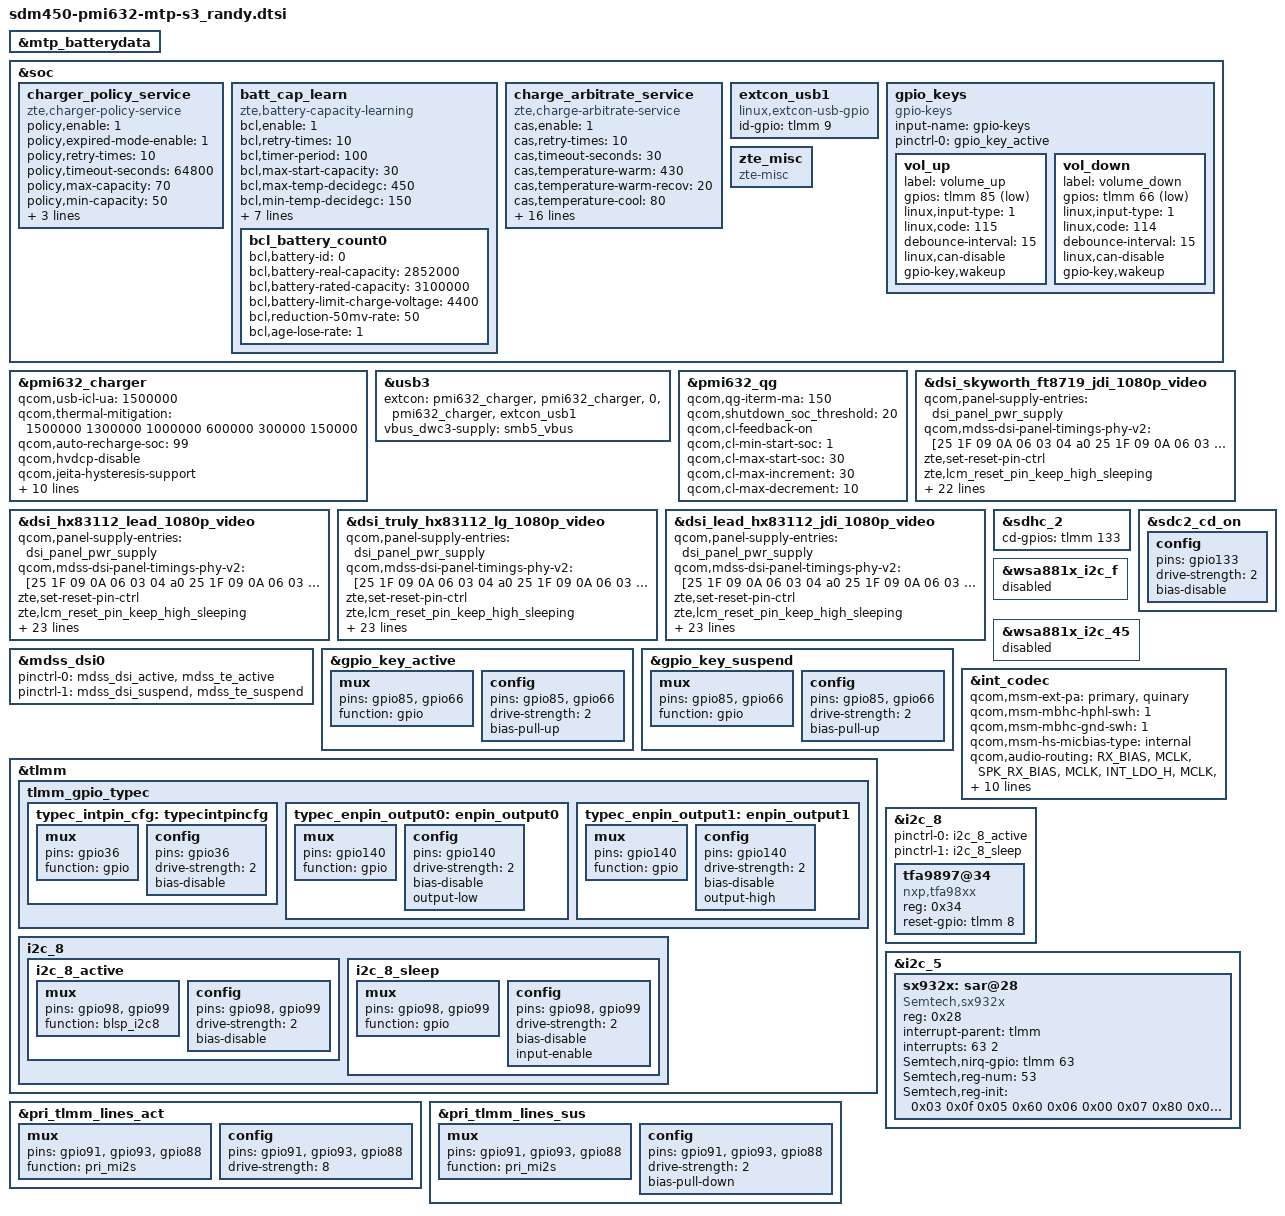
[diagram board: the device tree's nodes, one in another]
#include "dsi-panel-zte-lead-hx83112-lg-6p0-1080p-video-success.dtsi"
#include "dsi-panel-zte-truly-hx83112-lg-6p0-1080p-video.dtsi"
#include "dsi-panel-zte-lead-hx83112-jdi-6p0-1080p-video.dtsi"
#include "dsi-panel-zte-skyworth-ft8719-jdi-6p0-1080p-video.dtsi"

#include "zte-usb-type-c.dtsi"
#include "touchscreen-randy.dtsi"
#include "fingerprint_randy.dtsi"
#include "zte-sdm450-camera-sensor-mtp-randy.dtsi"

&mtp_batterydata {
	#include "zte_p450a01_3100mAh.dtsi"
};

&soc {
	charger_policy_service {
		compatible = "zte,charger-policy-service";
		policy,enable = <1>;
		policy,expired-mode-enable = <1>;
		policy,retry-times = <10>;
		policy,timeout-seconds = <64800>;/* 18 hours */
		policy,max-capacity = <70>;
		policy,min-capacity = <50>;
		policy,bms-phy-name = "bms";
		policy,battery-phy-name = "battery";
		policy,cas-phy-name = "cas";
	};

	batt_cap_learn {
		compatible = "zte,battery-capacity-learning";
		bcl,enable = <1>;
		bcl,retry-times = <10>;
		bcl,timer-period = <100>;/*ms*/
		bcl,max-start-capacity = <30>;
		bcl,max-temp-decidegc = <450>;
		bcl,min-temp-decidegc = <150>;
		bcl,max-limit-deciperc = <100>;
		bcl,min-limit-deciperc = <50>;
		bcl,max-increment-deciperc = <5>;
		bcl,max-decrement-deciperc = <5>;
		bcl,bms-phy-name = "bms";
		bcl,battery-phy-name = "battery";
		/*bit7: 0: use zte algorithm calc age; 1: use platform algorithm calc age*/
		/*bit4: enable zte algorithm*/
		/*bit3: enable platform algorithm*/
		/*bit0: platform algorithm mode 0: integral mode; 1: delta mode*/
		bcl,algorithm-select = <0x88>;

		bcl_battery_count0 {
			bcl,battery-id = <0>;
			/*"real capacity" = "rated capacity" - "voltage diff" - "topoff diff"*/
			/*TMB TEST REAL CAPACITY 92%*/
			bcl,battery-real-capacity = <2852000>;
			bcl,battery-rated-capacity = <3100000>;
			bcl,battery-limit-charge-voltage = <4400>;
			bcl,reduction-50mv-rate = <50>;/*rate * 10*/
			bcl,age-lose-rate = <1>;/*rate * 10*/
		};
	};

	charge_arbitrate_service {
		compatible = "zte,charge-arbitrate-service";
		cas,enable = <1>;
		cas,retry-times = <10>;
		cas,timeout-seconds = <30>;/*s*/
		cas,temperature-warm = <430>;
		cas,temperature-warm-recov = <20>;
		cas,temperature-cool = <80>;
		cas,temperature-cool-recov = <20>;
		cas,normal-topoff = <5>;
		cas,abnormal-topoff = <9>;
		cas,force-full-aging = <1>;
		cas,subsidiary-phy-name = "bms";
		cas,battery-phy-name = "battery";
		cas,bcl-phy-name = "bcl";
		cas,fcv-phy = "battery";
		cas,fcc-phy = "battery";
		cas,icl-phy = "battery";
		cas,topoff-phy = "battery";
		cas,recharge-soc-phy = "battery";
		cas,recharge-voltage-phy = "battery";
		cas,voltage-cc-cv-phy = "bms";
		/* age, fcv, fcc, rech_soc_1st, rech_soc_2st rech_vol_1st, rech_vol_2st **/
		cas,age-data = <100 4400000 2000000 99 95 0 0
				95 4380000 1800000 98 94 0 0
				90 4360000 1600000 97 93 0 0
				85 4340000 1400000 96 92 0 0
				80 4320000 1200000 95 91 0 0
				75 4300000 1000000 94 90 0 0>;
	};
};

&pmi632_charger {
	qcom,usb-icl-ua = <1500000>;
	qcom,thermal-mitigation
		= <1500000 1300000 1000000 600000
			300000 150000>;
	qcom,auto-recharge-soc = <99>;
	qcom,hvdcp-disable;
	qcom,jeita-hysteresis-support;

	/* COOL = 10 DegC, WARM = 45 DegC */
	qcom,jeita-soft-thresholds = <0x3772 0x12d2>;
	/* COLD = 0 DegC, HOT = 60 DegC */
	qcom,jeita-hard-thresholds = <0x45f5 0xb71>;

	/* COOL = 2 DegC, WARM = 60 DegC */
	qcom,jeita-cold-hysteresis-thresholds = <0x430E 0xB71>;
	/* COLD = 12 DegC, HOT = 45 DegC */
	qcom,jeita-cool-hysteresis-thresholds = <0x349E 0x12D2>;
	/* COOL = 10 DegC, WARM = 43 DegC */
	qcom,jeita-warm-hysteresis-thresholds = <0x3772 0x141E>;
	/* COLD = 0 DegC, HOT = 58 DegC */
	qcom,jeita-hot-hysteresis-thresholds = <0x45F5 0xC38>;
};

/*typec*/
&usb3 {
	extcon = <&pmi632_charger>, <&pmi632_charger>, <0>,
		<&pmi632_charger>, <&extcon_usb1>;
	vbus_dwc3-supply = <&smb5_vbus>;
};

&soc {
	extcon_usb1: extcon_usb1 {
		compatible = "linux,extcon-usb-gpio";
		id-gpio = <&tlmm 9 0>;
/*		pinctrl-names = "default";  */
/*		pinctrl-0 = <&usb_id_default>;*/
	};
};

/*typec*/

&pmi632_qg {
	qcom,qg-iterm-ma = <150>;
	qcom,shutdown_soc_threshold = <20>;
	qcom,cl-feedback-on;
	qcom,cl-min-start-soc = <1>;
	qcom,cl-max-start-soc = <30>;
	qcom,cl-max-increment = <30>;
	qcom,cl-max-decrement = <10>;
};

&dsi_skyworth_ft8719_jdi_1080p_video{
	qcom,panel-supply-entries = <&dsi_panel_pwr_supply>;
	qcom,mdss-dsi-panel-timings-phy-v2 = [25 1F 09 0A 06 03 04 a0
		25 1F 09 0A 06 03 04 a0
		25 1F 09 0A 06 03 04 a0
		25 1F 09 0A 06 03 04 a0
		25 1D 08 0A 06 03 04 a0];
	zte,set-reset-pin-ctrl;
	zte,lcm_reset_pin_keep_high_sleeping;
	zte,mdss-dsi-cabc-default-value = <0x02>;
	zte,mdss-dsi-cabc-off-command = [39 01 00 00 00 00 02 55 00
	];
	zte,mdss-dsi-cabc-low-command = [39 01 00 00 00 00 02 55 11
	];
	zte,mdss-dsi-cabc-medium-command = [39 01 00 00 00 00 02 55 12
	];
	zte,mdss-dsi-cabc-high-command = [39 01 00 00 00 00 02 55 13
	];
	zte,mdss-dsi-cabc-command-state = "dsi_lp_mode";
//	qcom,esd-check-enabled;
	qcom,mdss-dsi-panel-status-check-mode = "reg_read";
	qcom,mdss-dsi-panel-status-command = [06 01 00 01 00 00 01 0a];
	qcom,mdss-dsi-panel-status-command-state = "dsi_lp_mode";
	qcom,mdss-dsi-panel-status-value = <0x9c 0x9c 0x9c 0x9c>;
	qcom,mdss-dsi-panel-on-check-value = <0x9c 0x9c 0x9c 0x9c>;
	qcom,mdss-dsi-panel-status-read-length = <4>;
	qcom,mdss-dsi-panel-max-error-count = <3>;
};



&dsi_hx83112_lead_1080p_video{
	qcom,panel-supply-entries = <&dsi_panel_pwr_supply>;
	qcom,mdss-dsi-panel-timings-phy-v2 = [25 1F 09 0A 06 03 04 a0
		25 1F 09 0A 06 03 04 a0
		25 1F 09 0A 06 03 04 a0
		25 1F 09 0A 06 03 04 a0
		25 1D 08 0A 06 03 04 a0];
	zte,set-reset-pin-ctrl;
	zte,lcm_reset_pin_keep_high_sleeping;
	zte,mdss-dsi-cabc-default-value = <0x02>;
	zte,mdss-dsi-cabc-off-command = [39 01 00 00 00 00 02 55 00
	];
	zte,mdss-dsi-cabc-low-command = [39 01 00 00 00 00 02 55 11
	];
	zte,mdss-dsi-cabc-medium-command = [39 01 00 00 00 00 02 55 12
	];
	zte,mdss-dsi-cabc-high-command = [39 01 00 00 00 00 02 55 13
	];
	zte,mdss-dsi-cabc-command-state = "dsi_lp_mode";
	qcom,esd-check-enabled;
	qcom,mdss-dsi-panel-status-check-mode = "reg_read";
	qcom,mdss-dsi-panel-status-command = [06 01 00 01 00 00 01 0a];
	qcom,mdss-dsi-panel-status-command-state = "dsi_lp_mode";
	qcom,mdss-dsi-panel-status-value = <0x9d 0x9d 0x9d 0x9d>;
	qcom,mdss-dsi-panel-on-check-value = <0x9d 0x9d 0x9d 0x9d>;
	qcom,mdss-dsi-panel-status-read-length = <4>;
	qcom,mdss-dsi-panel-max-error-count = <3>;
};

&dsi_truly_hx83112_lg_1080p_video{
	qcom,panel-supply-entries = <&dsi_panel_pwr_supply>;
	qcom,mdss-dsi-panel-timings-phy-v2 = [25 1F 09 0A 06 03 04 a0
		25 1F 09 0A 06 03 04 a0
		25 1F 09 0A 06 03 04 a0
		25 1F 09 0A 06 03 04 a0
		25 1D 08 0A 06 03 04 a0];
	zte,set-reset-pin-ctrl;
	zte,lcm_reset_pin_keep_high_sleeping;
	zte,mdss-dsi-cabc-default-value = <0x02>;
	zte,mdss-dsi-cabc-off-command = [39 01 00 00 00 00 02 55 00
	];
	zte,mdss-dsi-cabc-low-command = [39 01 00 00 00 00 02 55 11
	];
	zte,mdss-dsi-cabc-medium-command = [39 01 00 00 00 00 02 55 12
	];
	zte,mdss-dsi-cabc-high-command = [39 01 00 00 00 00 02 55 13
	];
	zte,mdss-dsi-cabc-command-state = "dsi_lp_mode";
	qcom,esd-check-enabled;
	qcom,mdss-dsi-panel-status-check-mode = "reg_read";
	qcom,mdss-dsi-panel-status-command = [06 01 00 01 00 00 01 0a];
	qcom,mdss-dsi-panel-status-command-state = "dsi_lp_mode";
	qcom,mdss-dsi-panel-status-value = <0x9d 0x9d 0x9d 0x9d>;
	qcom,mdss-dsi-panel-on-check-value = <0x9d 0x9d 0x9d 0x9d>;
	qcom,mdss-dsi-panel-status-read-length = <4>;
	qcom,mdss-dsi-panel-max-error-count = <3>;
};

&dsi_lead_hx83112_jdi_1080p_video{
	qcom,panel-supply-entries = <&dsi_panel_pwr_supply>;
	qcom,mdss-dsi-panel-timings-phy-v2 = [25 1F 09 0A 06 03 04 a0
		25 1F 09 0A 06 03 04 a0
		25 1F 09 0A 06 03 04 a0
		25 1F 09 0A 06 03 04 a0
		25 1D 08 0A 06 03 04 a0];
	zte,set-reset-pin-ctrl;
	zte,lcm_reset_pin_keep_high_sleeping;
	zte,mdss-dsi-cabc-default-value = <0x02>;
	zte,mdss-dsi-cabc-off-command = [39 01 00 00 00 00 02 55 00
	];
	zte,mdss-dsi-cabc-low-command = [39 01 00 00 00 00 02 55 11
	];
	zte,mdss-dsi-cabc-medium-command = [39 01 00 00 00 00 02 55 12
	];
	zte,mdss-dsi-cabc-high-command = [39 01 00 00 00 00 02 55 13
	];
	zte,mdss-dsi-cabc-command-state = "dsi_lp_mode";
	qcom,esd-check-enabled;
	qcom,mdss-dsi-panel-status-check-mode = "reg_read";
	qcom,mdss-dsi-panel-status-command = [06 01 00 01 00 00 01 0a];
	qcom,mdss-dsi-panel-status-command-state = "dsi_lp_mode";
	qcom,mdss-dsi-panel-status-value = <0x9d 0x9d 0x9d 0x9d>;
	qcom,mdss-dsi-panel-on-check-value = <0x9d 0x9d 0x9d 0x9d>;
	qcom,mdss-dsi-panel-status-read-length = <4>;
	qcom,mdss-dsi-panel-max-error-count = <3>;
};


&mdss_dsi0 {
	pinctrl-0 = <&mdss_dsi_active &mdss_te_active>;
	pinctrl-1 = <&mdss_dsi_suspend &mdss_te_suspend>;
 };

&soc {
	gpio_keys {
		compatible = "gpio-keys";
		input-name = "gpio-keys";
		pinctrl-names = "default";
		pinctrl-0 = <&gpio_key_active>;

		/delete-node/ camera_focus;
		/delete-node/ camera_snapshot;
		vol_up {
			label = "volume_up";
			gpios = <&tlmm 85 0x1>;
			linux,input-type = <1>;
			linux,code = <115>;
			debounce-interval = <15>;
			linux,can-disable;
			gpio-key,wakeup;
		};
		vol_down {
			label = "volume_down";
			gpios = <&tlmm 66 0x1>;
			linux,input-type = <1>;
			linux,code = <114>;
			debounce-interval = <15>;
			linux,can-disable;
			gpio-key,wakeup;
		};
	};

	zte_misc {
		compatible = "zte-misc";
	};
};
&gpio_key_active {
	mux {
		pins = "gpio85", "gpio66";
		function = "gpio";
	};
	config {
		pins = "gpio85", "gpio66";
		drive-strength = <2>;
		bias-pull-up;
	};
};
&gpio_key_suspend {
	mux {
		pins = "gpio85", "gpio66";
		function = "gpio";
	};
	config {
		pins = "gpio85", "gpio66";
		drive-strength = <2>;
		bias-pull-up;
	};
};

&tlmm {
/* zte typec */
	tlmm_gpio_typec {
		typec_intpin_cfg: typecintpincfg {
				mux {
					pins = "gpio36";
					function = "gpio";
				};
				config {
					pins = "gpio36";
					drive-strength = <2>;
					bias-disable;
				};
		};
		typec_enpin_output0: enpin_output0 {
				mux {
					pins = "gpio140";
					function = "gpio";
				};
				config {
					pins = "gpio140";
					drive-strength = <2>;
					bias-disable;
					output-low;
				};
		};
		typec_enpin_output1: enpin_output1 {
				mux {
					pins = "gpio140";
					function = "gpio";
				};
				config {
					pins = "gpio140";
					drive-strength = <2>;
					bias-disable;
					output-high;
				};
		};
	};
/*zte typec */
};

/*zteadd by wangxiaomei for SD cd pin start*/
&sdhc_2 {
	cd-gpios = <&tlmm 133 0x0>;
};
&sdc2_cd_on {
	config {
		pins = "gpio133";
		drive-strength = <2>;
		bias-disable;
	};
};
/*zteadd by wangxiaomei for SD cd pin end*/

&pri_tlmm_lines_act {
	mux {
		pins = "gpio91", "gpio93", "gpio88";
		function = "pri_mi2s";
	};

	config {
		pins = "gpio91", "gpio93", "gpio88";
		drive-strength = <8>;
	};
};

&pri_tlmm_lines_sus {
	mux {
		pins = "gpio91", "gpio93", "gpio88";
		function = "pri_mi2s";
	};

	config {
		pins = "gpio91", "gpio93", "gpio88";
		drive-strength = <2>;
		bias-pull-down;
	};
};

&wsa881x_i2c_f {
	status = "disabled";
};

&wsa881x_i2c_45 {
	status = "disabled";

};

&int_codec {
	qcom,msm-ext-pa = "primary","quinary";
	qcom,msm-mbhc-hphl-swh = <1>;
	qcom,msm-mbhc-gnd-swh = <1>;
	qcom,msm-hs-micbias-type = "internal";
	qcom,audio-routing =
			"RX_BIAS", "MCLK",
			"SPK_RX_BIAS", "MCLK",
			"INT_LDO_H", "MCLK",
			"RX_I2S_CLK", "MCLK",
			"TX_I2S_CLK", "MCLK",
			"MIC BIAS External", "Handset Mic",
			"MIC BIAS Internal2", "Headset Mic",
			"MIC BIAS External", "Secondary Mic",
			"AMIC1", "MIC BIAS External",
			"AMIC2", "MIC BIAS Internal2",
			"AMIC3", "MIC BIAS External",
			"ADC1_IN", "ADC1_OUT",
			"ADC2_IN", "ADC2_OUT",
			"ADC3_IN", "ADC3_OUT",
			"PDM_IN_RX1", "PDM_OUT_RX1",
			"PDM_IN_RX2", "PDM_OUT_RX2",
			"PDM_IN_RX3", "PDM_OUT_RX3";
};

&i2c_8 {
	status = "okay";
	pinctrl-names = "i2c_active", "i2c_sleep";
	pinctrl-0 = <&i2c_8_active>;
	pinctrl-1 = <&i2c_8_sleep>;
	tfa9897@34 {
		compatible = "nxp,tfa98xx";
		reg = <0x34>;
		reset-gpio = <&tlmm 8 0x0>;
	};
};

&tlmm {
	i2c_8 {
		i2c_8_active: i2c_8_active {
			/* active state */
			mux {
				pins = "gpio98", "gpio99";
				function = "blsp_i2c8";
			};

			config {
				pins = "gpio98", "gpio99";
				drive-strength = <2>;
				bias-disable;
			};
		};

		i2c_8_sleep: i2c_8_sleep {
			/* suspended state */
			mux {
				pins = "gpio98", "gpio99";
				function = "gpio";
			};

			config {
				pins = "gpio98", "gpio99";
				drive-strength = <2>;
				bias-disable;
				input-enable;
			};
		};
	};

};

&i2c_5 {
	status = "okay";
	sx932x:sar@28 {
		compatible = "Semtech,sx932x";
		reg = <0x28>;
		interrupt-parent = <&tlmm>;
		interrupts = <63 2>;
		Semtech,nirq-gpio = <&tlmm 63 0x00>;
		status ="ok";
		Semtech,reg-num = <53>;
		Semtech,reg-init  = /bits/ 8 < 0x03 0x0f
			0x05 0x60
			0x06 0x00
			0x07 0x80
			0x08 0x00
			0x10 0x16
			0x14 0x00 /*PH0 to CS0 input*/
			0x15 0x00
			0x20 0x10 /*PH2 CS2-input,CS1-dync,CS0-HZ*/
			0x21 0x10
			0x22 0x00
			0x23 0x01
			0x24 0x17
			0x25 0x00
			0x26 0x01
			0x27 0x17
			0x28 0x3D
			0x29 0x27
			0x2A 0x1F
			0x2B 0x37
			0x2C 0x12
			0x2D 0x06
			0x30 0x0A
			0x31 0x08
			0x32 0x20
			0x33 0x20
			0x34 0x0B
			0x35 0x10
			0x36 0x20
			0x37 0x24
			0x40 0x00
			0x41 0x00
			0x42 0x00
			0x43 0x00
			0x44 0x00
			0x45 0x05
			0x46 0x00
			0x47 0x00
			0x48 0x00
			0x49 0x00
			0x4A 0x40
			0x4B 0x00
			0x4C 0x00
			0x4D 0x00
			0x4E 0x80
			0x4F 0x0C
			0x50 0x00
			0x51 0x00
			0x52 0x00
			0x53 0x00
			0x54 0x00
			0x60 0x01
			0x11 0x21>;
	};
};
